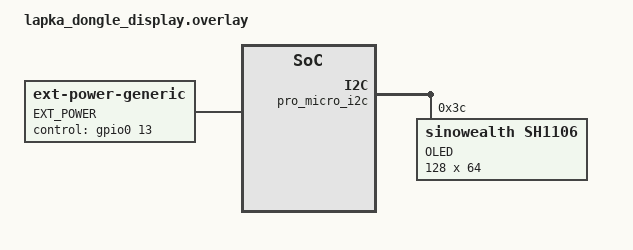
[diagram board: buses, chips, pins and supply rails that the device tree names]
#include <dt-bindings/zmk/matrix_transform.h>
#include "lapka-layouts.dtsi"
#include "lapka-transform.dtsi"

/ {
	chosen {
		zmk,physical-layout = &default_layout;
		zmk,kscan = &mock_kscan;
		zephyr,display = &oled;
	};

	ext_power_ctrl: ext-power {
		compatible = "zmk,ext-power-generic";
		label = "EXT_POWER";
		control-gpios = <&gpio0 13 GPIO_ACTIVE_HIGH>;
		init-delay-ms = <50>;
	};

	mock_kscan: mock_kscan_0 {
		compatible = "zmk,kscan-mock";
		columns = <0>;
		rows = <0>;
		events = <0>;
	};
};

// P0.17 (D2) - sda
// P0.20 (D3) - sck
&pro_micro_i2c {
	status = "okay";

	oled: sh1106@3c {
		compatible = "sinowealth,sh1106";
		reg = <0x3c>;
		label = "OLED";
		width = <128>;
		height = <64>;
		segment-offset = <2>;
		page-offset = <0>;
		display-offset = <0>;
		multiplex-ratio = <63>;
		inversion-on;
		prechargep = <0x22>;
	};
};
